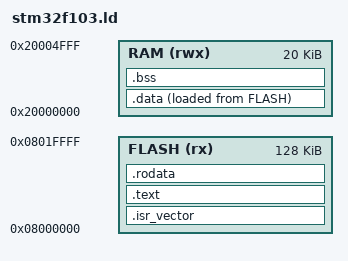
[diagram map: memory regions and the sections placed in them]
MEMORY
{
    FLASH (rx)  : ORIGIN = 0x08000000, LENGTH = 128K
    RAM   (rwx) : ORIGIN = 0x20000000, LENGTH = 20K
}

ENTRY(Reset_Handler)

SECTIONS
{
    .isr_vector :
    {
        KEEP(*(.vector_table))
    } > FLASH

    .text :
    {
        *(.text .text.*)
    } > FLASH

    .rodata :
    {
        *(.rodata .rodata.*)
    } > FLASH

    _sidata = LOADADDR(.data);

    .data : ALIGN(4)
    {
        _sdata = .;
        *(.data .data.*)
        . = ALIGN(4);
        _edata = .;
    } > RAM AT > FLASH

    .bss (NOLOAD) : ALIGN(4)
    {
        _sbss = .;
        *(.bss .bss.*)
        *(COMMON)
        . = ALIGN(4);
        _ebss = .;
    } > RAM

    /* AAPCS requires 8-byte SP alignment at exception entry; masking
     * here enforces it rather than relying on RAM size happening to be
     * a multiple of 8 (see CH04/example_01's link.x for the same idiom). */
    _stack_top = (ORIGIN(RAM) + LENGTH(RAM)) & ~7;
}
